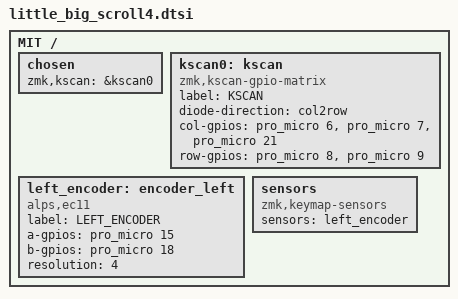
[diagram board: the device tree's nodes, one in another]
# Copyright (c) 2022 The ZMK Contributors
# SPDX-License-Identifier: MIT

#include <dt-bindings/zmk/matrix_transform.h>

/ {
    chosen {
        zmk,kscan = &kscan0;
    };

    kscan0: kscan {
        compatible = "zmk,kscan-gpio-matrix";
        label = "KSCAN";
        diode-direction = "col2row";

        col-gpios
            = <&pro_micro 6 GPIO_ACTIVE_HIGH> 
            , <&pro_micro 7 GPIO_ACTIVE_HIGH>
            , <&pro_micro 21 GPIO_ACTIVE_HIGH>
            ;

        row-gpios
            = <&pro_micro 8 (GPIO_ACTIVE_HIGH | GPIO_PULL_DOWN)>
            , <&pro_micro 9 (GPIO_ACTIVE_HIGH | GPIO_PULL_DOWN)>
            ;
    };
    
    left_encoder: encoder_left {
        compatible = "alps,ec11";
        label = "LEFT_ENCODER";
        a-gpios = <&pro_micro 15 (GPIO_ACTIVE_HIGH | GPIO_PULL_UP)>;
        b-gpios = <&pro_micro 18 (GPIO_ACTIVE_HIGH | GPIO_PULL_UP)>;
        resolution = <4>;
    };

    sensors {
        compatible = "zmk,keymap-sensors";
        sensors = <&left_encoder>;
    };
};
